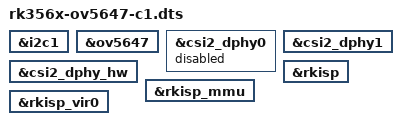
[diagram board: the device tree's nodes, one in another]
/dts-v1/;
/plugin/;

#include <dt-bindings/gpio/gpio.h>
#include <dt-bindings/pinctrl/rockchip.h>

/ {
	fragment@0 {
		target = <&i2c1>;

		__overlay__ {
        		status = "okay";
		};
	};

	fragment@1 {
		target = <&ov5647>;

		__overlay__ {
			status = "okay";
		};
	};

	fragment@2 {
		target = <&csi2_dphy0>;

		__overlay__ {
			status = "disabled";
		};
	};

	fragment@3 {
		target = <&csi2_dphy1>;

		__overlay__ {
			status = "okay";
		};
	};

	fragment@4 {
		target = <&csi2_dphy_hw>;

		__overlay__ {
			status = "okay";
		};
	};

	fragment@5 {
		target = <&rkisp>;

		__overlay__ {
			status = "okay";
		};
	};

	fragment@6 {
		target = <&rkisp_mmu>;
		__overlay__ {
			status = "okay";
		};
	};

	fragment@7 {
		target = <&rkisp_vir0>;
		__overlay__ {
        		status = "okay";
		};
	};
};
